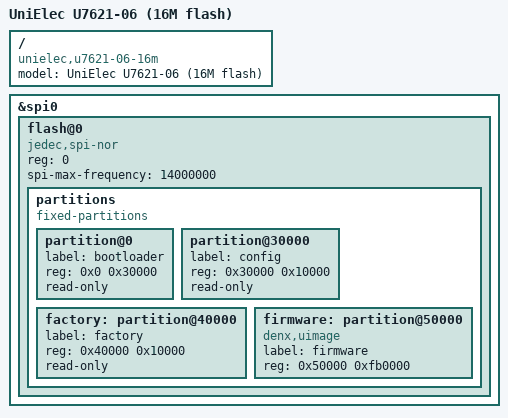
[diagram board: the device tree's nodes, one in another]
/*
 *  BSD LICENSE
 *
 *  Copyright(c) 2017 Kristian Evensen <kristian.evensen@gmail.com>.
 *  Copyright(c) 2017 Piotr Dymacz <pepe2k@gmail.com>.
 *  All rights reserved.
 *
 *  Redistribution and use in source and binary forms, with or without
 *  modification, are permitted provided that the following conditions
 *  are met:
 *
 *    * Redistributions of source code must retain the above copyright
 *      notice, this list of conditions and the following disclaimer.
 *    * Redistributions in binary form must reproduce the above copyright
 *      notice, this list of conditions and the following disclaimer in
 *      the documentation and/or other materials provided with the
 *      distribution.
 *    * Neither the name of Broadcom Corporation nor the names of its
 *      contributors may be used to endorse or promote products derived
 *      from this software without specific prior written permission.
 *
 *  THIS SOFTWARE IS PROVIDED BY THE COPYRIGHT HOLDERS AND CONTRIBUTORS
 *  "AS IS" AND ANY EXPRESS OR IMPLIED WARRANTIES, INCLUDING, BUT NOT
 *  LIMITED TO, THE IMPLIED WARRANTIES OF MERCHANTABILITY AND FITNESS FOR
 *  A PARTICULAR PURPOSE ARE DISCLAIMED. IN NO EVENT SHALL THE COPYRIGHT
 *  OWNER OR CONTRIBUTORS BE LIABLE FOR ANY DIRECT, INDIRECT, INCIDENTAL,
 *  SPECIAL, EXEMPLARY, OR CONSEQUENTIAL DAMAGES (INCLUDING, BUT NOT
 *  LIMITED TO, PROCUREMENT OF SUBSTITUTE GOODS OR SERVICES; LOSS OF USE,
 *  DATA, OR PROFITS; OR BUSINESS INTERRUPTION) HOWEVER CAUSED AND ON ANY
 *  THEORY OF LIABILITY, WHETHER IN CONTRACT, STRICT LIABILITY, OR TORT
 *  (INCLUDING NEGLIGENCE OR OTHERWISE) ARISING IN ANY WAY OUT OF THE USE
 *  OF THIS SOFTWARE, EVEN IF ADVISED OF THE POSSIBILITY OF SUCH DAMAGE.
 */

/dts-v1/;

#include "mt7621_unielec_u7621-06.dtsi"

/ {
	compatible = "unielec,u7621-06-16m", "unielec,u7621-06", "mediatek,mt7621-soc";
	model = "UniElec U7621-06 (16M flash)";
};

&spi0 {
	status = "okay";

	flash@0 {
		compatible = "jedec,spi-nor";
		reg = <0>;
		spi-max-frequency = <14000000>;

		partitions {
			compatible = "fixed-partitions";
			#address-cells = <1>;
			#size-cells = <1>;

			partition@0 {
				label = "bootloader";
				reg = <0x0 0x30000>;
				read-only;
			};

			partition@30000 {
				label = "config";
				reg = <0x30000 0x10000>;
				read-only;
			};

			factory: partition@40000 {
				label = "factory";
				reg = <0x40000 0x10000>;
				read-only;
			};

			firmware: partition@50000 {
				compatible = "denx,uimage";
				label = "firmware";
				reg = <0x50000 0xfb0000>;
			};
		};
	};
};
